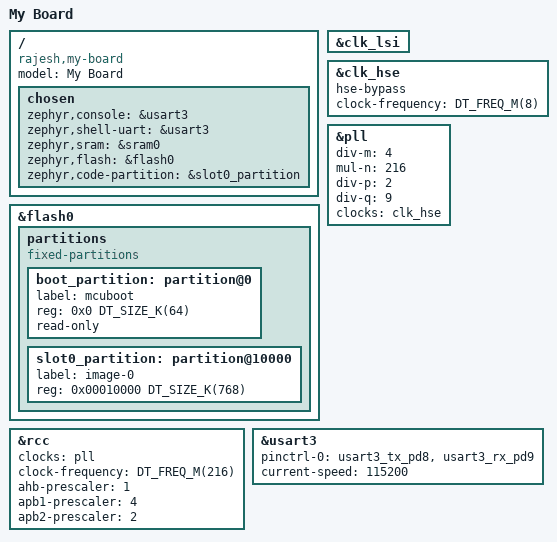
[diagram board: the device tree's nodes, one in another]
/dts-v1/;

#include <st/f7/stm32f767Xi.dtsi>
#include <st/f7/stm32f767zitx-pinctrl.dtsi>
#include <zephyr/dt-bindings/input/input-event-codes.h>

/ {
    model = "My Board";
    compatible = "rajesh,my-board";
    chosen {
		zephyr,console = &usart3;
		zephyr,shell-uart = &usart3;
		zephyr,sram = &sram0;
		zephyr,flash = &flash0;
        zephyr,code-partition = &slot0_partition;
    };
};

&flash0 {
    partitions {
        compatible = "fixed-partitions";
        #address-cells = <1>;
        #size-cells = <1>;

        boot_partition: partition@0 {
            label = "mcuboot";
            reg = <0x0 DT_SIZE_K(64)>;
            read-only;
        };

        slot0_partition: partition@10000 {
            label = "image-0";
            reg = <0x00010000 DT_SIZE_K(768)>;
        };
    };
};

&clk_lsi {
	status = "okay";
};

&clk_hse {
	hse-bypass;
	clock-frequency = <DT_FREQ_M(8)>; /* STLink 8MHz clock */
	status = "okay";
};

&pll {
	div-m = <4>;
	mul-n = <216>;
	div-p = <2>;
	div-q = <9>;
	clocks = <&clk_hse>;
	status = "okay";
};

&rcc {
	clocks = <&pll>;
	clock-frequency = <DT_FREQ_M(216)>;
	ahb-prescaler = <1>;
	apb1-prescaler = <4>;
	apb2-prescaler = <2>;
};

&usart3 {
	pinctrl-0 = <&usart3_tx_pd8 &usart3_rx_pd9>;
	pinctrl-names = "default";
	current-speed = <115200>;
	status = "okay";
};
